# MKW38A4 register map
Vendor: NXP Semiconductors; Series: Kinetis_W; File version: 1.6
CPU: CM0PLUS r0p0, little endian, no MPU, no FPU, VTOR, 2 interrupt priority bits
Registers are 32-bit, read-write, no defined reset value unless marked. A register's access mark holds for its fields unless they carry their own. Offsets are from the block's base; [hi:lo] are bit positions; {n}, {i} and the like mark numbered series; 'fields as' and 'values as' point back to an identical list.

## PORTC — PORT
Base 0x4004B000
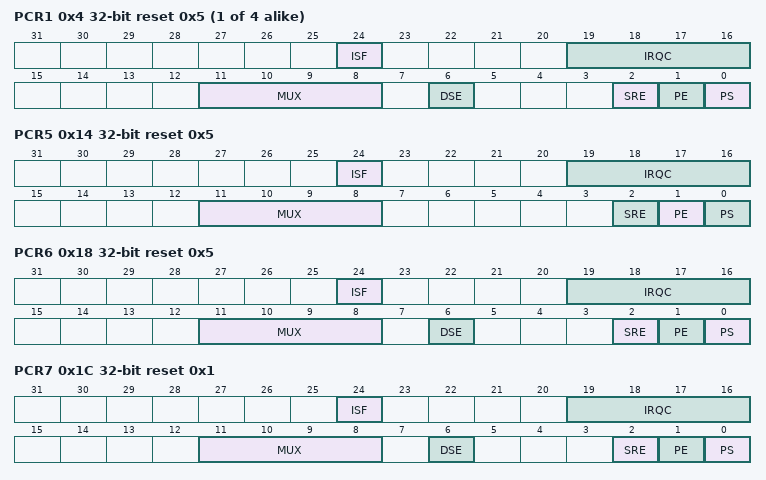
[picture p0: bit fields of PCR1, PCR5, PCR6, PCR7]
{0x0+4i} PCR{i} reset 0x5 (i=1..4) — Pin Control Register {i}
  [24] ISF — Interrupt Status Flag
    0=Configured interrupt is not detected
  [19:16] IRQC — Interrupt Configuration
    0=Interrupt Status Flag (ISF) is disabled; 1=ISF flag and DMA request on rising edge; 2=ISF flag and DMA request on falling edge; 3=ISF flag and DMA request on either edge; 8=ISF flag and Interrupt when logic 0; 9=ISF flag and Interrupt on rising-edge; 10=ISF flag and Interrupt on falling-edge; 11=ISF flag and Interrupt on either edge; 12=ISF flag and Interrupt when logic 1
  [11:8] MUX — Pin Mux Control
    0=Pin disabled (Alternative 0) (analog); 1=Alternative 1 (GPIO); {v}=Alternative {v} (chip-specific) (v=2..15)
  [6] DSE — Drive Strength Enable
    0=Low drive strength is configured on the corresponding pin, if pin is configured as a digital output; 1=High drive strength is configured on the corresponding pin, if pin is configured as a digital output
  [2] SRE — Slew Rate Enable
    0=Fast slew rate is configured on the corresponding pin, if the pin is configured as a digital output; 1=Slow slew rate is configured on the corresponding pin, if the pin is configured as a digital output
  [1] PE — Pull Enable
  [0] PS — Pull Select
    0=Internal pulldown resistor is enabled on the corresponding pin, if the corresponding PE field is set; 1=Internal pullup resistor is enabled on the corresponding pin, if the corresponding PE field is set
0x14 PCR5 reset 0x5 — Pin Control Register 5
  [24] ISF — Interrupt Status Flag
    0=Configured interrupt is not detected
  [19:16] IRQC — Interrupt Configuration
    values as PCR1.IRQC
  [11:8] MUX — Pin Mux Control
    values as PCR1.MUX
  [2] SRE — Slew Rate Enable
    values as PCR1.SRE
  [1] PE — Pull Enable
  [0] PS — Pull Select
    values as PCR1.PS
0x18 PCR6 reset 0x5 — Pin Control Register 6
  fields as PCR1
0x1C PCR7 reset 0x1 — Pin Control Register 7
  fields as PCR1
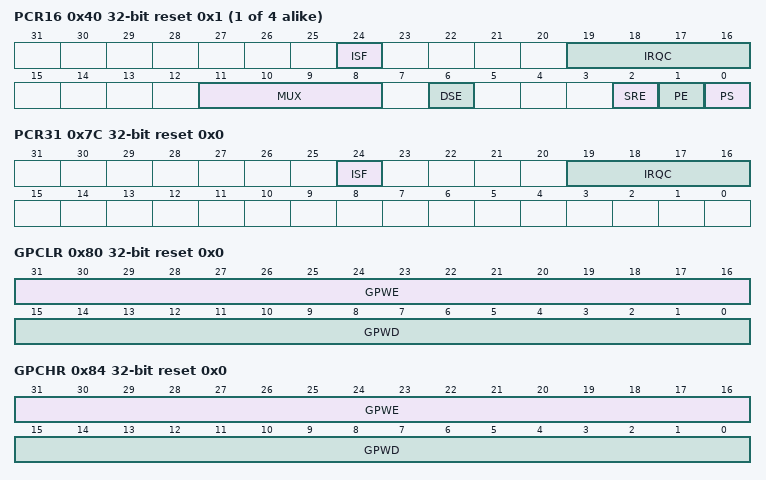
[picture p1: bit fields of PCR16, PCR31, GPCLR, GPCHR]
{0x0+4i} PCR{i} reset 0x1 (i=16..19) — Pin Control Register {i}
  fields as PCR1
0x7C PCR31 reset 0x0 — Pin Control Register 31
  [24] ISF — Interrupt Status Flag
    0=Configured interrupt is not detected
  [19:16] IRQC — Interrupt Configuration
    values as PCR1.IRQC
0x80 GPCLR reset 0x0 — Global Pin Control Low Register
  [31:16] GPWE — Global Pin Write Enable
  [15:0] GPWD — Global Pin Write Data
0x84 GPCHR reset 0x0 — Global Pin Control High Register
  fields as GPCLR
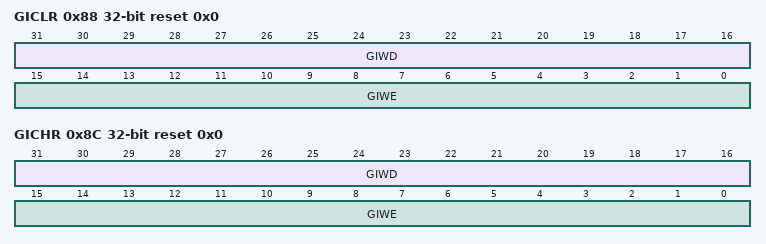
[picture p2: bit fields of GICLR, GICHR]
0x88 GICLR reset 0x0 — Global Interrupt Control Low Register
  [31:16] GIWD — Global Interrupt Write Data
  [15:0] GIWE — Global Interrupt Write Enable
0x8C GICHR reset 0x0 — Global Interrupt Control High Register
  fields as GICLR
0xA0 ISFR reset 0x0 — Interrupt Status Flag Register
  [31:0] ISF — Interrupt Status Flag

## DSB
Base 0x4005B000
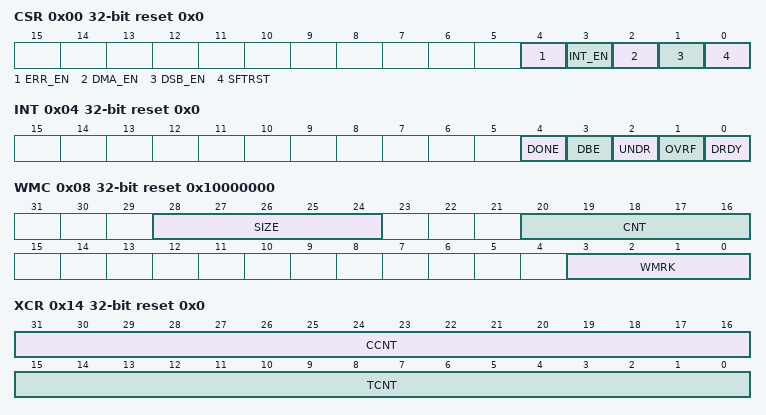
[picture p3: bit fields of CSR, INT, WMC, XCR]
0x00 CSR reset 0x0 — Control Register
  [4] ERR_EN — Error Interrupt Request Enable
    0=Error interrupt requests on overflow, underrun, or bus error are disabled; 1=Error interrupt requests on overflow, underrun, or bus error are enabled
  [3] INT_EN — Interrupt Request Enable
    0=Interrupt requests on data ready or DMA done are disabled
  [2] DMA_EN — DMA Transfer Enable
    0=DMA transfers are disabled; 1=DMA transfers are enabled
  [1] DSB_EN — Data Stream Buffer Enable
    0=Buffer is disabled; 1=Buffer is enabled
  [0] SFTRST — Soft Reset
    0=No operation; 1=Reset the data stream buffer
0x04 INT reset 0x0 — Interrupt Request Status Register
  [4] DONE — DMA Packet Transfer Complete
    0=Packet transfer not done; CCNT less than TCNT; 1=Packet transfer is done; TCNT 32-bit words transferred
  [3] DBE — Destination Bus Error
    0=No destination bus error; 1=The last recorded error is bus error on a write
  [2] UNDR — Underrun Error
    0=No underrun error; 1=The last recorded error is an underrun on a read
  [1] OVRF — Overflow Error
    0=No overflow error; 1=The last recorded error is a buffer overflow
  [0] DRDY ro — Data Ready
    0=No data to read (watermark has not been reached); 1=Data is ready to read (watermark has been reached)
0x08 WMC reset 0x10000000 — Watermark Configuration Register
  [28:24] SIZE ro — FIFO size
  [20:16] CNT ro — FIFO Count
  [3:0] WMRK — Watermark
0x0C RDATA ro reset 0x0 — FIFO Read Data Register
  [31:0] DATA — FIFO Data
0x10 DADDR reset 0x0 — DMA Destination Address Register
  [31:0] DADDR — Destination Address
0x14 XCR reset 0x0 — DMA Transfer Count Register
  [31:16] CCNT ro — Current Transfer Count
  [15:0] TCNT — Total Transfer Count
